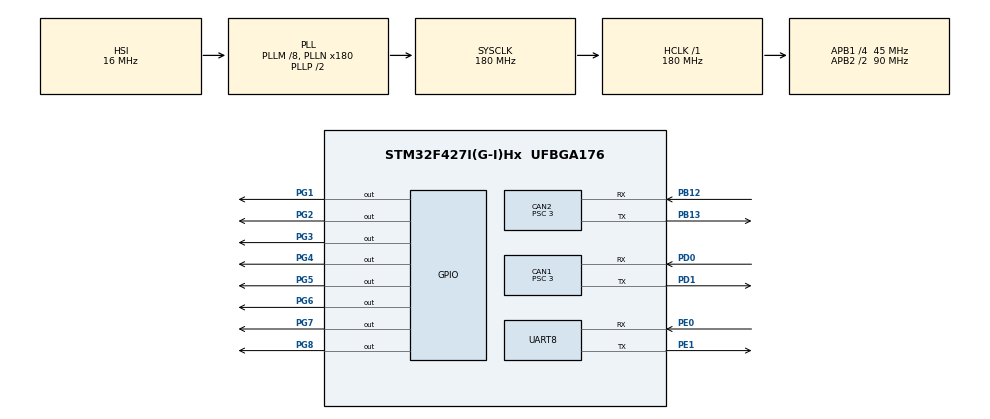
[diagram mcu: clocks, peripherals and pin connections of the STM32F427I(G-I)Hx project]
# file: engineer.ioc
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CAN1.ABOM=ENABLE
CAN1.AWUM=ENABLE
CAN1.BS1=CAN_BS1_12TQ
CAN1.BS2=CAN_BS2_2TQ
CAN1.CalculateBaudRate=1000000
CAN1.CalculateTimeBit=1000
CAN1.CalculateTimeQuantum=66.66666666666666
CAN1.NART=DISABLE
CAN1.Prescaler=3
CAN1.TXFP=ENABLE
CAN2.ABOM=ENABLE
CAN2.AWUM=ENABLE
CAN2.BS1=CAN_BS1_12TQ
CAN2.BS2=CAN_BS2_2TQ
CAN2.CalculateBaudRate=1000000
CAN2.CalculateTimeBit=1000
CAN2.CalculateTimeQuantum=66.66666666666666
CAN2.NART=ENABLE
CAN2.Prescaler=3
CAN2.TXFP=ENABLE
Mcu.Family=STM32F4
Mcu.Name=STM32F427I(G-I)Hx
Mcu.Package=UFBGA176
NVIC.CAN1_RX0_IRQn=true\:0\:0\:false\:false\:true\:true\:true\:true
NVIC.CAN1_SCE_IRQn=true\:0\:0\:false\:false\:true\:true\:true\:true
NVIC.CAN2_RX0_IRQn=true\:0\:0\:false\:false\:true\:true\:true\:true
NVIC.CAN2_SCE_IRQn=true\:0\:0\:false\:false\:true\:true\:true\:true
NVIC.PriorityGroup=NVIC_PRIORITYGROUP_4
PB12.Mode=CAN_Activate
PB12.Signal=CAN2_RX
PB13.Mode=CAN_Activate
PB13.Signal=CAN2_TX
PD0.GPIO_Speed=GPIO_SPEED_FREQ_VERY_HIGH
PD0.Mode=CAN_Activate
PD0.Signal=CAN1_RX
PD1.GPIO_Speed=GPIO_SPEED_FREQ_VERY_HIGH
PD1.Mode=CAN_Activate
PD1.Signal=CAN1_TX
PE0.Mode=Asynchronous
PE0.Signal=UART8_RX
PE1.Mode=Asynchronous
PE1.Signal=UART8_TX
PG1.Signal=GPIO_Output
PG2.Signal=GPIO_Output
PG3.Signal=GPIO_Output
PG4.Signal=GPIO_Output
PG5.Signal=GPIO_Output
PG6.Signal=GPIO_Output
PG7.Signal=GPIO_Output
PG8.Signal=GPIO_Output
PH0/OSC_IN.Mode=HSE-External-Oscillator
PH0/OSC_IN.Signal=RCC_OSC_IN
PH1/OSC_OUT.Mode=HSE-External-Oscillator
PH1/OSC_OUT.Signal=RCC_OSC_OUT
ProjectManager.HeapSize=0x200
ProjectManager.StackSize=0x400
ProjectManager.TargetToolchain=CMake
RCC.48MHZClocksFreq_Value=90000000
RCC.AHBFreq_Value=180000000
RCC.APB1CLKDivider=RCC_HCLK_DIV4
RCC.APB1Freq_Value=45000000
RCC.APB1TimFreq_Value=90000000
RCC.APB2CLKDivider=RCC_HCLK_DIV2
RCC.APB2Freq_Value=90000000
RCC.APB2TimFreq_Value=180000000
RCC.CortexFreq_Value=180000000
RCC.HCLKFreq_Value=180000000
RCC.HSE_VALUE=25000000
RCC.HSI_VALUE=16000000
RCC.LSE_VALUE=32768
RCC.PLLM=8
RCC.PLLN=180
RCC.SYSCLKFreq_VALUE=180000000
RCC.SYSCLKSource=RCC_SYSCLKSOURCE_PLLCLK
RCC.VCOOutputFreq_Value=360000000
UART8.VirtualMode=Asynchronous
board=custom

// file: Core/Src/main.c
/* USER CODE BEGIN Header */
/**
  ******************************************************************************
  * @file           : main.c
  * @brief          : Main program body
  ******************************************************************************
  * @attention
  *
  * Copyright (c) 2026 STMicroelectronics.
  * All rights reserved.
  *
  * This software is licensed under terms that can be found in the LICENSE file
  * in the root directory of this software component.
  * If no LICENSE file comes with this software, it is provided AS-IS.
  *
  ******************************************************************************
  */
/* USER CODE END Header */
#include "main.h"
#include "can.h"
#include "gpio.h"
#include "usart.h"

void SystemClock_Config(void);
/* USER CODE BEGIN PFP */
// extern void main_cpp();
/* USER CODE END PFP */

/* USER CODE BEGIN 0 */
extern void main_cpp(void);
/* USER CODE END 0 */

int main(void) {

    /* MCU Configuration--------------------------------------------------------*/

    /* Reset of all peripherals, Initializes the Flash interface and the Systick. */
    HAL_Init();

    /* Configure the system clock */
    SystemClock_Config();

    /* Initialize all configured peripherals */
    MX_GPIO_Init();
    MX_CAN1_Init();
    MX_CAN2_Init();
    MX_UART8_Init();
    /* USER CODE BEGIN 2 */
    main_cpp();
    /* USER CODE END 2 */

    /* Infinite loop */
    while (1) {

    }
}

void SystemClock_Config(void) {
    RCC_OscInitTypeDef RCC_OscInitStruct = {0};
    RCC_ClkInitTypeDef RCC_ClkInitStruct = {0};

    /** Configure the main internal regulator output voltage
  */
    __HAL_RCC_PWR_CLK_ENABLE();
    __HAL_PWR_VOLTAGESCALING_CONFIG(PWR_REGULATOR_VOLTAGE_SCALE1);

    /** Initializes the RCC Oscillators according to the specified parameters
  * in the RCC_OscInitTypeDef structure.
  */
    RCC_OscInitStruct.OscillatorType = RCC_OSCILLATORTYPE_HSI;
    RCC_OscInitStruct.HSIState = RCC_HSI_ON;
    RCC_OscInitStruct.HSICalibrationValue = RCC_HSICALIBRATION_DEFAULT;
    RCC_OscInitStruct.PLL.PLLState = RCC_PLL_ON;
    RCC_OscInitStruct.PLL.PLLSource = RCC_PLLSOURCE_HSI;
    RCC_OscInitStruct.PLL.PLLM = 8;
    RCC_OscInitStruct.PLL.PLLN = 180;
    RCC_OscInitStruct.PLL.PLLP = RCC_PLLP_DIV2;
    RCC_OscInitStruct.PLL.PLLQ = 4;
    if (HAL_RCC_OscConfig(&RCC_OscInitStruct) != HAL_OK) {
        Error_Handler();
    }

    /** Activate the Over-Drive mode
  */
    if (HAL_PWREx_EnableOverDrive() != HAL_OK) {
        Error_Handler();
    }

    /** Initializes the CPU, AHB and APB buses clocks
  */
    RCC_ClkInitStruct.ClockType = RCC_CLOCKTYPE_HCLK | RCC_CLOCKTYPE_SYSCLK |
                                  RCC_CLOCKTYPE_PCLK1 | RCC_CLOCKTYPE_PCLK2;
    RCC_ClkInitStruct.SYSCLKSource = RCC_SYSCLKSOURCE_PLLCLK;
    RCC_ClkInitStruct.AHBCLKDivider = RCC_SYSCLK_DIV1;
    RCC_ClkInitStruct.APB1CLKDivider = RCC_HCLK_DIV4;
    RCC_ClkInitStruct.APB2CLKDivider = RCC_HCLK_DIV2;

    if (HAL_RCC_ClockConfig(&RCC_ClkInitStruct, FLASH_LATENCY_5) != HAL_OK) {
        Error_Handler();
    }
}

void Error_Handler(void) {
    __disable_irq();
    while (1) {}
}
